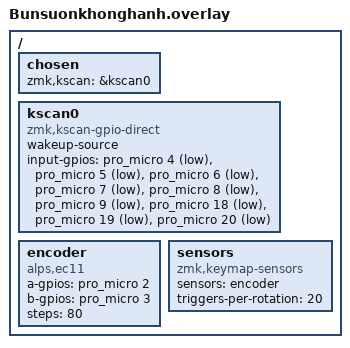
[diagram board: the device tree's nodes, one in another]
/*
 * Copyright (c) 2026 The ZMK Contributors
 * SPDX-License-Identifier: MIT
 */

/ {
    chosen {
        zmk,kscan = &kscan0;
    };

    kscan0: kscan0 {
        compatible = "zmk,kscan-gpio-direct";
        wakeup-source;

        input-gpios
            = <&pro_micro 4 (GPIO_ACTIVE_LOW | GPIO_PULL_UP)>   /* Nút chính 1 */
            , <&pro_micro 5 (GPIO_ACTIVE_LOW | GPIO_PULL_UP)>   /* Nút chính 2 */
            , <&pro_micro 6 (GPIO_ACTIVE_LOW | GPIO_PULL_UP)>   /* Nút chính 3 */
            , <&pro_micro 7 (GPIO_ACTIVE_LOW | GPIO_PULL_UP)>   /* Nút chính 4 */
            , <&pro_micro 8 (GPIO_ACTIVE_LOW | GPIO_PULL_UP)>   /* Nút chính 5 */
            , <&pro_micro 9 (GPIO_ACTIVE_LOW | GPIO_PULL_UP)>   /* Nút chính 6 */
            , <&pro_micro 18 (GPIO_ACTIVE_LOW | GPIO_PULL_UP)>  /* Nút phụ 1: Bluetooth (Giữ 5s) */
            , <&pro_micro 19 (GPIO_ACTIVE_LOW | GPIO_PULL_UP)>  /* Nút phụ 2: Chuyển layer */
            , <&pro_micro 20 (GPIO_ACTIVE_LOW | GPIO_PULL_UP)>  /* Nút nhấn EC11: Mute/Unmute */
            ;
    };

    encoder: encoder {
        compatible = "alps,ec11";
        a-gpios = <&pro_micro 2 (GPIO_ACTIVE_HIGH | GPIO_PULL_UP)>;
        b-gpios = <&pro_micro 3 (GPIO_ACTIVE_HIGH | GPIO_PULL_UP)>;
        steps = <80>;
        status = "okay";
    };

    sensors: sensors {
        compatible = "zmk,keymap-sensors";
        sensors = <&encoder>;
        triggers-per-rotation = <20>;
    };
};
